AUTOSAR XML (schema 314)
package /ComponentType
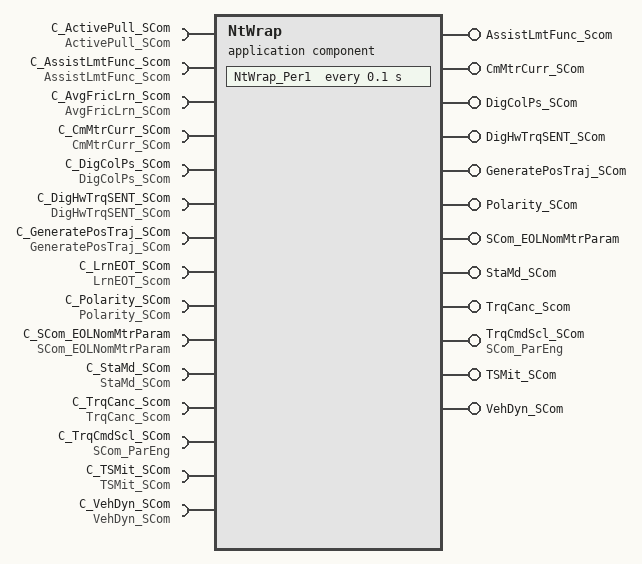
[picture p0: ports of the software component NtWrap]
  application software component type NtWrap
    12 x provide port:
      AssistLmtFunc_Scom: provided-interface=AssistLmtFunc_Scom
        provided-com-specs:
          operation=GetSteeringAssistDefeat, queue-length=1
          operation=ManualTrqCmd, queue-length=1
          operation=SetSteeringAssistDefeat, queue-length=1
      CmMtrCurr_SCom: provided-interface=CmMtrCurr_SCom
        provided-com-specs:
          operation=CalGain, queue-length=1
          operation=CalOffset, queue-length=1
          operation=MtrCurrOffReadStatus, queue-length=1
          operation=ReadMtrCurrCals, queue-length=1
          operation=SetMtrCurrCals, queue-length=1
      DigColPs_SCom: provided-interface=DigColPs_SCom
        provided-com-specs:
          operation=CustClearTrim, queue-length=1
          operation=CustSetTrim, queue-length=1
          operation=NxtClrTrim, queue-length=1
          operation=NxtSetTrim, queue-length=1
      DigHwTrqSENT_SCom: provided-interface=DigHwTrqSENT_SCom
        provided-com-specs:
          operation=ClrTrqTrim, queue-length=1
          operation=SetTrqTrim, queue-length=1
          operation=TrimData, queue-length=1
          operation=WriteData, queue-length=1
      GeneratePosTraj_SCom: server-com-spec{operation=SetInputParam, queue-length=1}, provided-interface=GeneratePosTraj_SCom
      Polarity_SCom: provided-com-specs=[{operation=ReadPolarity, queue-length=1}, {operation=SetPolarity, queue-length=1}], provided-interface=Polarity_SCom
      SCom_EOLNomMtrParam: provided-com-specs=[{operation=Get, queue-length=1}, {operation=Set, queue-length=1}], provided-interface=SCom_EOLNomMtrParam
      StaMd_SCom: server-com-spec{operation=EcuReset, queue-length=1}, provided-interface=StaMd_SCom
      TrqCanc_Scom: provided-interface=TrqCanc_Scom
        provided-com-specs:
          operation=ReadCogTrqCal, queue-length=1
          operation=ReadCogTrqCalComp, queue-length=1
          operation=SetCogTrqCal, queue-length=1
          operation=SetCogTrqCalComp, queue-length=1
      TrqCmdScl_SCom: provided-com-specs=[{operation=Get, queue-length=1}, {operation=Set, queue-length=1}], provided-interface=SCom_ParEng
      TSMit_SCom: provided-interface=TSMit_SCom
        provided-com-specs:
          operation=GainReset, queue-length=1
          operation=GetFcnDefeat, queue-length=1
          operation=GetLongTermGains, queue-length=1
          operation=GetLrnDefeat, queue-length=1
          operation=SetFcnDefeat, queue-length=1
          operation=SetLongTermGains, queue-length=1
          operation=SetLrnDefeat, queue-length=1
      VehDyn_SCom: provided-com-specs=[{operation=ForceCenter, queue-length=1}, {operation=ResetCenter, queue-length=1}], provided-interface=VehDyn_SCom
    15 x require port:
      C_ActivePull_SCom: required-com-specs=[ReadParam, Reset, SetLTComp, SetSTComp], required-interface=ActivePull_SCom
      C_AssistLmtFunc_Scom: required-com-specs=[GetSteeringAssistDefeat, ManualTrqCmd, SetSteeringAssistDefeat], required-interface=AssistLmtFunc_Scom
      C_AvgFricLrn_Scom: required-interface=AvgFricLrn_SCom
        required-com-specs:
          CaptureOnTheFly
          GetEOLFric
          GetOffsetOutputDefeat
          GetSelect
          InitLearnedTables
          ResetToZero
          SetEOLFric
          SetOffsetOutputDefeat
          SetSelect
      C_CmMtrCurr_SCom: required-com-specs=[CalGain, CalOffset, MtrCurrOffReadStatus, ReadMtrCurrCals, SetMtrCurrCals], required-interface=CmMtrCurr_SCom
      C_DigColPs_SCom: required-com-specs=[CustClearTrim, CustSetTrim, NxtClrTrim, NxtSetTrim], required-interface=DigColPs_SCom
      C_DigHwTrqSENT_SCom: required-com-specs=[ClrTrqTrim, SetTrqTrim, TrimData, WriteData], required-interface=DigHwTrqSENT_SCom
      C_GeneratePosTraj_SCom: client-com-spec=SetInputParam, required-interface=GeneratePosTraj_SCom
      C_LrnEOT_SCom: required-com-specs=[ResetEOT, ResetRckCntrPrf], required-interface=LrnEOT_Scom
      C_Polarity_SCom: required-com-specs=[ReadPolarity, SetPolarity], required-interface=Polarity_SCom
      C_SCom_EOLNomMtrParam: required-com-specs=[Get, Set], required-interface=SCom_EOLNomMtrParam
      C_StaMd_SCom: client-com-spec=EcuReset, required-interface=StaMd_SCom
      C_TrqCanc_Scom: required-com-specs=[ReadCogTrqCal, ReadCogTrqCalComp, SetCogTrqCal, SetCogTrqCalComp], required-interface=TrqCanc_Scom
      C_TrqCmdScl_SCom: required-com-specs=[Get, Set], required-interface=SCom_ParEng
      C_TSMit_SCom: required-com-specs=[GainReset, GetFcnDefeat, GetLongTermGains, GetLrnDefeat, SetFcnDefeat, SetLongTermGains, SetLrnDefeat], required-interface=TSMit_SCom
      C_VehDyn_SCom: required-com-specs=[ForceCenter, ResetCenter], required-interface=VehDyn_SCom
  internal behavior NtWrap_InternalBehavior: component=NtWrap
    12 x operation invoked event:
      OIT_AssistLmtFunc_Scom_ManualTrqCmd_AssistLmtFunc_Scom_ManualTrqCmd: start-on-event=AssistLmtFunc_Scom_ManualTrqCmd, operation=AssistLmtFunc_Scom.ManualTrqCmd
      OIT_CmMtrCurr_SCom_CalGain_CmMtrCurr_SCom_CalGain: start-on-event=CmMtrCurr_SCom_CalGain, operation=CmMtrCurr_SCom.CalGain
      OIT_CmMtrCurr_SCom_CalOffset_CmMtrCurr_SCom_CalOffset: start-on-event=CmMtrCurr_SCom_CalOffset, operation=CmMtrCurr_SCom.CalOffset
      OIT_CmMtrCurr_SCom_SetMtrCurrCals_CmMtrCurr_SCom_SetMtrCurrCals: start-on-event=CmMtrCurr_SCom_SetMtrCurrCals, operation=CmMtrCurr_SCom.SetMtrCurrCals
      OIT_DigColPs_SCom_CustClrTrim_DigColPs_SCom_CustClearTrim: start-on-event=DigColPs_SCom_CustClrTrim, operation=DigColPs_SCom.CustClearTrim
      OIT_DigColPs_SCom_CustSetTrim_DigColPs_SCom_CustSetTrim: start-on-event=DigColPs_SCom_CustSetTrim, operation=DigColPs_SCom.CustSetTrim
      OIT_DigColPs_SCom_NxtClearTrim_DigColPs_SCom_NxtClrTrim: start-on-event=DigColPs_SCom_NxtClearTrim, operation=DigColPs_SCom.NxtClrTrim
      OIT_DigColPs_SCom_NxtSetTrim_DigColPs_SCom_NxtSetTrim: start-on-event=DigColPs_SCom_NxtSetTrim, operation=DigColPs_SCom.NxtSetTrim
      OIT_DigHwTrqSENT_SCom_ClrTrqTrim_DigHwTrqSENT_SCom_ClrTrqTrim: start-on-event=DigHwTrqSENT_SCom_ClrTrqTrim, operation=DigHwTrqSENT_SCom.ClrTrqTrim
      OIT_DigHwTrqSENT_SCom_SetTrqTrim_DigHwTrqSENT_SCom_SetTrqTrim: start-on-event=DigHwTrqSENT_SCom_SetTrqTrim, operation=DigHwTrqSENT_SCom.SetTrqTrim
      OIT_DigHwTrqSENT_SCom_WriteData_DigHwTrqSENT_SCom_WriteData: start-on-event=DigHwTrqSENT_SCom_WriteData, operation=DigHwTrqSENT_SCom.WriteData
      OIT_GeneratePosTraj_SCom_SetInputParam_GeneratePosTraj_SCom_SetInputParam: start-on-event=GeneratePosTraj_SCom_SetInputParam, operation=GeneratePosTraj_SCom.SetInputParam
    timing event TMT_NtWrap_Per1: start-on-event=NtWrap_Per1, period=0.1
    6 x operation invoked event:
      OIT_Polarity_SCom_SetPolarity_Polarity_SCom_SetPolarity: start-on-event=Polarity_SCom_SetPolarity, operation=Polarity_SCom.SetPolarity
      OIT_SCom_EOLNomMtrParam_Set_SCom_EOLNomMtrParam_Set: start-on-event=SCom_EOLNomMtrParam_Set, operation=SCom_EOLNomMtrParam.Set
      OIT_TrqCanc_Scom_SetCogTrqCal_TrqCanc_Scom_SetCogTrqCal: start-on-event=TrqCanc_Scom_SetCogTrqCal, operation=TrqCanc_Scom.SetCogTrqCal
      OIT_TrqCmdScl_SCom_Set_TrqCmdScl_SCom_Set: start-on-event=TrqCmdScl_SCom_Set, operation=TrqCmdScl_SCom.Set
      OIT_TSMit_SCom_GainReset_TSMit_SCom_GainReset: start-on-event=TSMit_SCom_GainReset, operation=TSMit_SCom.GainReset
      OIT_VehDyn_SCom_ForceCenter_VehDyn_SCom_ForceCenter: start-on-event=VehDyn_SCom_ForceCenter, operation=VehDyn_SCom.ForceCenter
    port-api-options:
      enable-take-address=false, indirect-api=false, port=AssistLmtFunc_Scom
      enable-take-address=false, indirect-api=false, port=C_ActivePull_SCom
      enable-take-address=false, indirect-api=false, port=C_AssistLmtFunc_Scom
      enable-take-address=false, indirect-api=false, port=C_AvgFricLrn_Scom
      enable-take-address=false, indirect-api=false, port=C_CmMtrCurr_SCom
      enable-take-address=false, indirect-api=false, port=C_DigColPs_SCom
      enable-take-address=false, indirect-api=false, port=C_DigHwTrqSENT_SCom
      enable-take-address=false, indirect-api=false, port=C_GeneratePosTraj_SCom
      enable-take-address=false, indirect-api=false, port=C_LrnEOT_SCom
      enable-take-address=false, indirect-api=false, port=C_Polarity_SCom
      enable-take-address=false, indirect-api=false, port=C_SCom_EOLNomMtrParam
      enable-take-address=false, indirect-api=false, port=C_StaMd_SCom
      enable-take-address=false, indirect-api=false, port=C_TrqCanc_Scom
      enable-take-address=false, indirect-api=false, port=C_TrqCmdScl_SCom
      enable-take-address=false, indirect-api=false, port=C_TSMit_SCom
      enable-take-address=false, indirect-api=false, port=C_VehDyn_SCom
      enable-take-address=false, indirect-api=false, port=CmMtrCurr_SCom
      enable-take-address=false, indirect-api=false, port=DigColPs_SCom
      enable-take-address=false, indirect-api=false, port=DigHwTrqSENT_SCom
      enable-take-address=false, indirect-api=false, port=GeneratePosTraj_SCom
      enable-take-address=false, indirect-api=false, port=Polarity_SCom
      enable-take-address=false, indirect-api=false, port=SCom_EOLNomMtrParam
      enable-take-address=false, indirect-api=false, port=StaMd_SCom
      enable-take-address=false, indirect-api=false, port=TrqCanc_Scom
      enable-take-address=false, indirect-api=false, port=TrqCmdScl_SCom
      enable-take-address=false, indirect-api=false, port=TSMit_SCom
      enable-take-address=false, indirect-api=false, port=VehDyn_SCom
    19 x runnable:
      AssistLmtFunc_Scom_ManualTrqCmd: symbol=NtWrapC_AssistLmtFunc_Scom_ManualTrqCmd
        sync call SC_C_AssistLmtFunc_Scom_ManualTrqCmd: operation=C_AssistLmtFunc_Scom.ManualTrqCmd, timeout=0
      CmMtrCurr_SCom_CalGain: symbol=NtWrapC_CmMtrCurr_SCom_CalGain
        sync call SC_C_CmMtrCurr_SCom_CalGain: operation=C_CmMtrCurr_SCom.CalGain, timeout=0
      CmMtrCurr_SCom_CalOffset: symbol=NtWrapC_CmMtrCurr_SCom_CalOffset
        sync call SC_C_CmMtrCurr_SCom_CalOffset: operation=C_CmMtrCurr_SCom.CalOffset, timeout=0
      CmMtrCurr_SCom_SetMtrCurrCals: symbol=NtWrapC_CmMtrCurr_SCom_SetMtrCurrCals
        sync call SC_C_CmMtrCurr_SCom_SetMtrCurrCals: operation=C_CmMtrCurr_SCom.SetMtrCurrCals, timeout=0
      DigColPs_SCom_CustClrTrim: symbol=NtWrapC_DigColPs_SCom_CustClrTrim
        sync call SC_C_DigColPs_SCom_CustClearTrim: operation=C_DigColPs_SCom.CustClearTrim, timeout=0
      DigColPs_SCom_CustSetTrim: symbol=NtWrapC_DigColPs_SCom_CustSetTrim
        sync call SC_C_DigColPs_SCom_CustSetTrim: operation=C_DigColPs_SCom.CustSetTrim, timeout=0
      DigColPs_SCom_NxtClearTrim: symbol=NtWrapC_DigColPs_SCom_NxtClrTrim
        sync call SC_C_DigColPs_SCom_NxtClrTrim: operation=C_DigColPs_SCom.NxtClrTrim, timeout=0
      DigColPs_SCom_NxtSetTrim: symbol=NtWrapC_DigColPs_SCom_NxtSetTrim
        sync call SC_C_DigColPs_SCom_NxtSetTrim: operation=C_DigColPs_SCom.NxtSetTrim, timeout=0
      DigHwTrqSENT_SCom_ClrTrqTrim: symbol=NtWrapC_DigHwTrqSENT_SCom_ClrTrqTrim
        sync call SC_C_DigHwTrqSENT_SCom_ClrTrqTrim: operation=C_DigHwTrqSENT_SCom.ClrTrqTrim, timeout=0
      DigHwTrqSENT_SCom_SetTrqTrim: symbol=NtWrapC_DigHwTrqSENT_SCom_SetTrqTrim
        sync call SC_C_DigHwTrqSENT_SCom_SetTrqTrim: operation=C_DigHwTrqSENT_SCom.SetTrqTrim, timeout=0
      DigHwTrqSENT_SCom_WriteData: symbol=NtWrapC_DigHwTrqSENT_SCom_WriteData
        sync call SC_C_DigHwTrqSENT_SCom_WriteData: operation=C_DigHwTrqSENT_SCom.WriteData, timeout=0
      GeneratePosTraj_SCom_SetInputParam: symbol=NtWrapC_GeneratePosTraj_SCom_SetInputParam
        sync call SC_C_GeneratePosTraj_SCom_SetInputParam: operation=C_GeneratePosTraj_SCom.SetInputParam, timeout=0
      NtWrap_Per1  # Dummy function to map this component onto an application for generation.
      Polarity_SCom_SetPolarity: symbol=NtWrapC_Polarity_SCom_SetPolarity
        sync call SC_C_Polarity_SCom_SetPolarity: operation=C_Polarity_SCom.SetPolarity, timeout=0
      SCom_EOLNomMtrParam_Set: symbol=NtWrapC_SCom_EOLNomMtrParam_Set
        sync call SC_C_SCom_EOLNomMtrParam_Set: operation=C_SCom_EOLNomMtrParam.Set, timeout=0
      TrqCanc_Scom_SetCogTrqCal: symbol=NtWrapC_TrqCanc_Scom_SetCogTrqCal
        sync call SC_C_TrqCanc_Scom_SetCogTrqCal: operation=C_TrqCanc_Scom.SetCogTrqCal, timeout=0
      TrqCmdScl_SCom_Set: symbol=NtWrapC_TrqCmdScl_SCom_Set
        sync call SC_C_TrqCmdScl_SCom_Set: operation=C_TrqCmdScl_SCom.Set, timeout=0
      TSMit_SCom_GainReset: symbol=NtWrapC_TSMit_SCom_GainReset
        sync call SC_C_TSMit_SCom_GainReset: operation=C_TSMit_SCom.GainReset, timeout=0
      VehDyn_SCom_ForceCenter: symbol=NtWrapC_VehDyn_SCom_ForceCenter
        sync call SC_C_VehDyn_SCom_ForceCenter: operation=C_VehDyn_SCom.ForceCenter, timeout=0
  swc implementation NtWrap_Implementation: behavior=NtWrap_InternalBehavior
    code-descriptors:
      code Code: type=SRC
